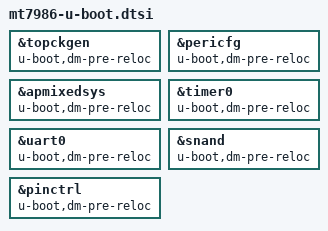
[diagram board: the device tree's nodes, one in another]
// SPDX-License-Identifier: GPL-2.0
/*
 * Copyright (c) 2022 MediaTek Inc.
 * Author: Sam Shih <sam.shih@mediatek.com>
 */

&topckgen {
	u-boot,dm-pre-reloc;
};

&pericfg {
	u-boot,dm-pre-reloc;
};

&apmixedsys {
	u-boot,dm-pre-reloc;
};

&timer0 {
	u-boot,dm-pre-reloc;
};

&uart0 {
	u-boot,dm-pre-reloc;
};

&snand {
	u-boot,dm-pre-reloc;
};

&pinctrl {
	u-boot,dm-pre-reloc;
};
